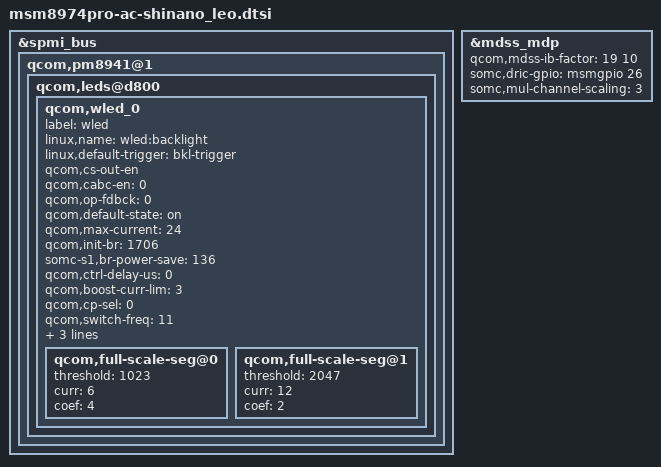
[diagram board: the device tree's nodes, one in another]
/* arch/arm/boot/dts/qcom/msm8974pro-ac-shinano_leo.dtsi
 *
 * Copyright (C) 2014 Sony Mobile Communications Inc.
 *
 * This program is free software; you can redistribute it and/or modify
 * it under the terms of the GNU General Public License version 2 and
 * only version 2 as published by the Free Software Foundation.
 *
 * This program is distributed in the hope that it will be useful,
 * but WITHOUT ANY WARRANTY; without even the implied warranty of
 * MERCHANTABILITY or FITNESS FOR A PARTICULAR PURPOSE.  See the
 * GNU General Public License for more details.
 */

&spmi_bus {
	qcom,pm8941@1 {
		qcom,leds@d800 {
			status = "okay";
			qcom,wled_0 {
				label = "wled";
				linux,name = "wled:backlight";
				linux,default-trigger = "bkl-trigger";
				qcom,cs-out-en;
				qcom,cabc-en = <0>;
				qcom,op-fdbck = <0>;
				qcom,default-state = "on";
				qcom,max-current = <24>;
				qcom,init-br = <1706>;
				somc-s1,br-power-save = <136>;
				qcom,ctrl-delay-us = <0>;
				qcom,boost-curr-lim = <3>;
				qcom,cp-sel = <0>;
				qcom,switch-freq = <11>;
				qcom,ovp-val = <2>;
				qcom,num-strings = <2>;
				qcom,id = <0>;
				qcom,full-scale-seg@0 {
					threshold = <1023>;
					curr = <6>;
					coef = <4>;
				};
				qcom,full-scale-seg@1 {
					threshold = <2047>;
					curr = <12>;
					coef = <2>;
				};
			};
		};
	};
};

&mdss_mdp {
	qcom,mdss-ib-factor = <19 10>;
	somc,dric-gpio = <&msmgpio 26 0>;
	somc,mul-channel-scaling = <3>;
};
